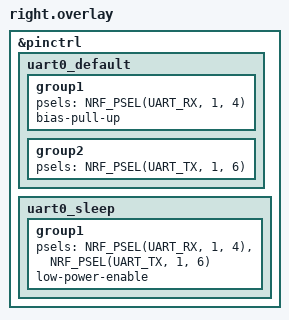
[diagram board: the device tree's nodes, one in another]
&pinctrl {
    uart0_default: uart0_default {
        group1 {
            psels = <NRF_PSEL(UART_RX, 1, 4)>; // RX = P1.04
            bias-pull-up;
        };
        group2 {
            psels = <NRF_PSEL(UART_TX, 1, 6)>; // TX = P1.06
        };
    };

    uart0_sleep: uart0_sleep {
        group1 {
            psels = <NRF_PSEL(UART_RX, 1, 4)>,
                    <NRF_PSEL(UART_TX, 1, 6)>;
            low-power-enable;
        };
    };
};

